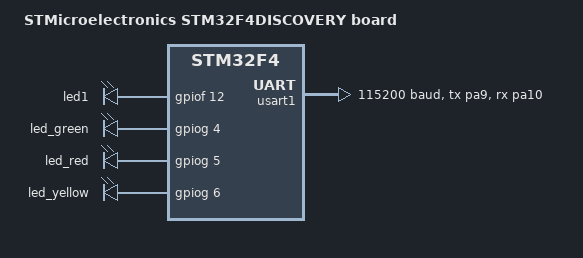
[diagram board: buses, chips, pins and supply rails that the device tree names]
/ {
	model = "STMicroelectronics STM32F4DISCOVERY board";
	compatible = "st,stm32f4discovery";

	chosen {
		zephyr,console = &usart1;
		zephyr,shell-uart = &usart1;
	};

	leds {
		compatible = "gpio-leds";
		led1: led_1 {
			gpios = <&gpiof 12 GPIO_ACTIVE_HIGH>;
		};
		led_green: led_green {
			gpios = <&gpiog 4 GPIO_ACTIVE_HIGH>;
		};
		led_red: led_red {
			gpios = <&gpiog 5 GPIO_ACTIVE_HIGH>;
		};
		led_yellow: led_yellow {
			gpios = <&gpiog 6 GPIO_ACTIVE_HIGH>;
		};
	};

	aliases {
		led1 = &led1;
		console = &usart1;
	};
};

&usart1 {
	pinctrl-0 = <&usart1_tx_pa9 &usart1_rx_pa10>;
	pinctrl-names = "default";
	current-speed = <115200>;
	status = "okay";
};
